VERSION "demo"

NS_ :

BS_: 500 : 1,2

BU_: ECM Gateway

VAL_TABLE_ Gear 0 "Park" 1 "Reverse" 2 "Neutral" 3 "Drive" ;

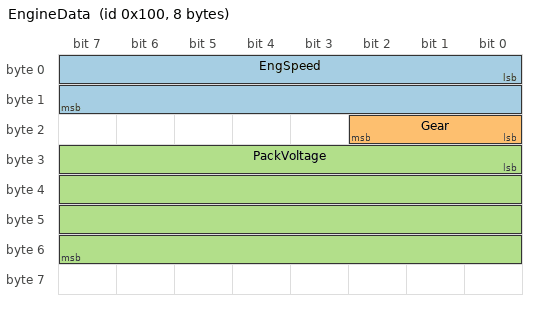
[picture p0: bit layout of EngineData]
BO_ 256 EngineData : 8 ECM
 SG_ EngSpeed : 0|16@1+ (0.25,0) [0|8000] "rpm" Gateway
 SG_ Gear : 16|3@1+ (1,0) [0|7] "" Gateway
 SG_ PackVoltage : 24|32@1+ (1,0) [0|0] "V" Gateway

SGTYPE_ TempType : 16@1- (0.1,-40) [-40|125] "degC" 0 , Gear ;
SGTYPE_VAL_ TempType 0 "Cold" 1 "Hot" ;
SIGTYPE_VALTYPE_ TempType : 0 ;
BA_DEF_SGTYPE_ "SgTypeKind" ENUM "Temperature","Pressure","Speed" ;
BA_SGTYPE_ "SgTypeKind" TempType "Temperature" ;
SIG_TYPE_REF_ 256 EngSpeed : TempType ;

SIG_GROUP_ 256 EngineGroup 1 : EngSpeed Gear ;
SIG_VALTYPE_ 256 PackVoltage : 1 ;
SIG_VALTYPE_ 256 Gear 0 ;

CM_ "powertrain" ;
CM_ BU_ ECM "engine controller" ;
CM_ BO_ 256 "10 ms engine data" ;
CM_ SG_ 256 EngSpeed "crank speed" ;

BA_DEF_ "BusType" STRING ;
BA_DEF_ BO_ "GenMsgCycleTime" INT 0 65535 ;
BA_DEF_ BO_ "VFrameFormat" ENUM "StandardCAN","ExtendedCAN","J1939PG","StandardCAN_FD","ExtendedCAN_FD" ;
BA_DEF_ SG_ "GenSigStartValue" FLOAT 0 100000 ;
BA_DEF_DEF_ "BusType" "CAN" ;
BA_DEF_DEF_ "GenMsgCycleTime" 0 ;
BA_DEF_DEF_ "VFrameFormat" "StandardCAN" ;
BA_DEF_DEF_ "GenSigStartValue" 0 ;
BA_ "GenMsgCycleTime" BO_ 256 10 ;

BA_DEF_REL_ BU_SG_REL_ "GenSigTimeoutTime" INT 0 65535 ;
BA_DEF_DEF_REL_ "GenSigTimeoutTime" 0 ;
BA_REL_ "GenSigTimeoutTime" BU_SG_REL_ Gateway SG_ 256 EngSpeed 100 ;
BA_REL_ "GenMsgTimeoutTime" BU_BO_REL_ ECM 256 50 ;

EV_ SimStatus : 0 [0|1] "" 0 1 DUMMY_NODE_VECTOR0 ECM ;
EV_DATA_ SimStatus : 4 ;

VAL_ 256 Gear 0 "Park" 1 "Reverse" 2 "Neutral" 3 "Drive" ;
